# Clock_Control_Reg_CM register map
Vendor: Texas Instruments
Peripheral module from a debugger description file (folder omap34xx).
Registers are 32-bit, access per field, reset 0x0 unless marked. A register's access mark holds for its fields unless they carry their own. Offsets are as the file gives them; lines under a group give offsets from that group; [hi:lo] are bit positions; {n}, {i} and the like mark numbered series; 'fields as' and 'values as' point back to an identical list; <NAME> marks a mode.

## Clock_Control_Reg_CM
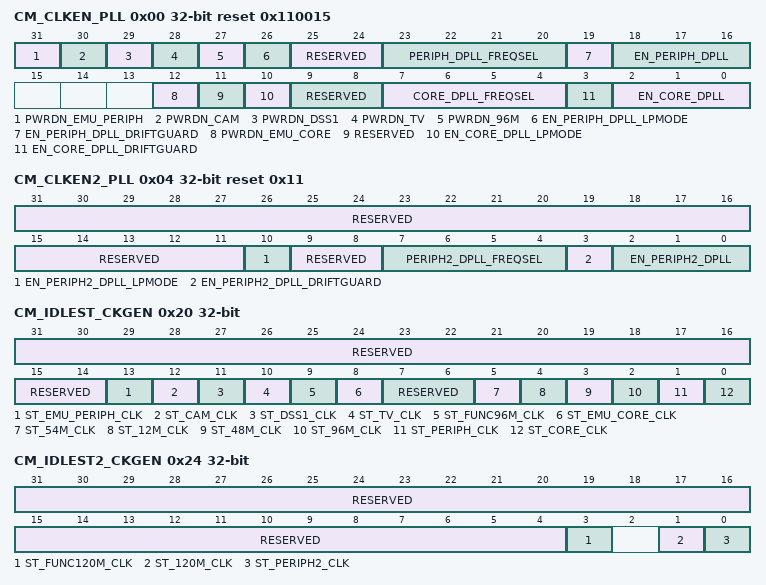
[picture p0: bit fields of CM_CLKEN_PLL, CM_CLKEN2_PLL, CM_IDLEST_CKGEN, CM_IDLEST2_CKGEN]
0x00 CM_CLKEN_PLL reset 0x110015 — This register allows controlling the DPLL3 and DPLL4 modes.
  [31] PWRDN_EMU_PERIPH rw — This bit allows to power-down or not the DPLL4_M6X2_CLK HSDIVIDER path.
    0=Power-up the DPLL4_M6X2_CLK HSDIVIDER path; 1=Power-down the DPLL4_M6X2_CLK HSDIVIDER path. Writting this bit to 1 will take effect immediatly.
  [30] PWRDN_CAM rw — This bit allows to power-down or not the DPLL4_M5X2_CLK HSDIVIDER path.
    0=Power-up the DPLL4_M5X2_CLK HSDIVIDER path; 1=Power-down the DPLL4_M5X2_CLK HSDIVIDER path. Writting this bit to 1 will take effect immediatly.
  [29] PWRDN_DSS1 rw — This bit allows to power-down or not the DPLL4_M4X2_CLK HSDIVIDER path.
    0=Power-up the DPLL4_M4X2_CLK HSDIVIDER path; 1=Power-down the DPLL4_M4X2_CLK HSDIVIDER path. Writting this bit to 1 will take effect immediatly.
  [28] PWRDN_TV rw — This bit allows to power-down or not the DPLL4_M3X2_CLK HSDIVIDER path.
    0=Power-up the DPLL4_M3X2_CLK HSDIVIDER path; 1=Power-down the DPLL4_M3X2_CLK HSDIVIDER path. Writting this bit to 1 will take effect immediatly.
  [27] PWRDN_96M rw — This bit allows to power-down or not the DPLL4_M2X2_CLK path.
    0=Power-up the DPLL4_M2X2_CLK path; 1=Power-down the DPLL4_M2X2_CLK path. Writting this bit to 1 will take effect immediatly.
  [26] EN_PERIPH_DPLL_LPMODE rw — This bit allows to enable or disable the LP mode of the DPLL4. Writting this bit to switch the mode between LP or normal mode will take effect only when the DPLL will have transition into the bypass or stop state, followed by a lock or re-lock of the DPLL.
    0=Disables the DPLL LP mode to re-enter the normal mode at the following lock or re-lock sequence; 1=Enables the DPLL LP mode to enter the LP mode at the following lock or re-lock sequence
  [25:24] RESERVED rw — Write 0s for future compatibility. Read returns 0.
  [23:20] PERIPH_DPLL_FREQSEL rw — This bit field allows selecting the proper range of the DPLL4 internal frequency depending on the DPLL reference clock and the N divider.
    3=0.75 MHz 1.0 MHz0x4: 1.0 MHz 1.25 MHz 0x5: 1.25 MHz 1.5 MHz 0x6: 1.5 MHz 1.75 MHz 0x7: 1.75 MHz 2.1 MHz 0xB: 7.5 MHz 10 MHz 0xC: 10 MHz 12.5 MHz 0xD: 12.5 MHz 15 MHz 0xE: 15 MHz 17.5 MHz 0xF: 17.5 MHz 21 MHz
  [19] EN_PERIPH_DPLL_DRIFTGUARD rw — This bit allows to enable or disable the automatic recalibration feature of the DPLL4. The DPLL4 will automatically start a recalibration process upon assertion of the recal flag if this bit is set.
    0=Disables the DPLL4 automatic recalibration mode; 1=Enables the DPLL4 automatic recalibration mode
  [18:16] EN_PERIPH_DPLL rw — DPLL4 control; Other enums: Reserved
    1=Put the DPLL4 in low power stop mode; 7=Enables the DPLL4 in lock mode
  [12] PWRDN_EMU_CORE rw — This bit allows to power-down or not the DPLL3_M3X2 HSDIVIDER path.
    0=Power-up the DPLL3_M3X2 HSDIVIDER path; 1=Power-down the DPLL3_M3X2 HSDIVIDER path. Writting this bit to 1 will take effect immediatly.
  [11] RESERVED ro — Write 0s for future compatibility. Read returns 0.
  [10] EN_CORE_DPLL_LPMODE rw — This bit allows to enable or disable the LP mode of the DPLL3. Writting this bit to switch the mode between LP or normal mode will take effect only when the DPLL will have transition into the bypass or stop state, followed by a lock or re-lock of the DPLL.
    values as EN_PERIPH_DPLL_LPMODE
  [9:8] RESERVED rw — Write 0s for future compatibility. Read returns 0.
  [7:4] CORE_DPLL_FREQSEL rw — This bit field allows selecting the proper range of the DPLL3 internal frequency depending on the DPLL reference clock and the N divider.
    values as PERIPH_DPLL_FREQSEL
  [3] EN_CORE_DPLL_DRIFTGUARD rw — This bit allows to enable or disable the automatic recalibration feature of the DPLL3. The DPLL3 will automatically start a recalibration process upon assertion of the recal flag if this bit is set.
    0=Disables the DPLL3 automatic recalibration mode; 1=Enables the DPLL3 automatic recalibration mode
  [2:0] EN_CORE_DPLL rw — DPLL3 control; Other enums: Reserved
    5=Put the DPLL3 in low power bypass; 6=Put the DPLL3 in fast relock bypass; 7=Enables the DPLL3 in lock mode
0x04 CM_CLKEN2_PLL reset 0x11 — This register controls the DPLL5 modes.
  [31:11] RESERVED ro — Write 0s for future compatibility. Read returns 0.
  [10] EN_PERIPH2_DPLL_LPMODE rw — This bit allows to enable or disable the LP mode of the DPLL5. Writting this bit to switch the mode between LP or normal mode will take effect only when the DPLL will have transition into the bypass or stop state, followed by a lock or re-lock of the DPLL.
    values as CM_CLKEN_PLL.EN_PERIPH_DPLL_LPMODE
  [9:8] RESERVED rw — Write 0s for future compatibility. Read returns 0.
  [7:4] PERIPH2_DPLL_FREQSEL rw — This bit field allows selecting the proper range of the second PERIPHERAL DPLL internal frequency depending on the DPLL reference clock and the N divider.
    values as CM_CLKEN_PLL.PERIPH_DPLL_FREQSEL
  [3] EN_PERIPH2_DPLL_DRIFTGUARD rw — This bit allows to enable or disable the automatic recalibration feature of the DPLL5. The DPLL5 will automatically start a recalibration process upon assertion of the recal flag if this bit is set.
    0=Disables the DPLL5 automatic recalibration mode; 1=Enables the DPLL5 automatic recalibration mode
  [2:0] EN_PERIPH2_DPLL rw — DPLL5 control; Other enums: Reserved
    1=Put the second DPLL5 in low power stop mode; 7=Enables the DPLL5 in lock mode
0x20 CM_IDLEST_CKGEN ro — This register allows monitoring the master clock activity. This register is read only and automatically updated.
  [31:14] RESERVED — Read returns 0.
  [13] ST_EMU_PERIPH_CLK — Emulation clock activity at the output stage of the DPLL4
    0=EMU_PER_ALWON_CLK is not active; 1=EMU_PER_ALWON_CLK is active
  [12] ST_CAM_CLK — CAMERA functional clock activity at the output stage of the DPLL4
    0=CAM_MCLK is not active; 1=CAM_MCLK is active
  [11] ST_DSS1_CLK — DSS functional clock 1 activity at the output stage of the DPLL4
    0=DSS1_ALWON_FCLK is not active; 1=DSS1_ALWON_FCLK is active
  [10] ST_TV_CLK — TV clock activity at the output stage of the DPLL4
    0=DPLL4_M3X2_CLK is not active; 1=DPLL4_M3X2_CLK is active
  [9] ST_FUNC96M_CLK — 96 MHz clock activity at the output stage of the DPLL4
    0=DPLL4_M2X2_CLK is not active; 1=DPLL4_M2X2_CLK is active
  [8] ST_EMU_CORE_CLK — Emulation clock activity at the output stage of the DPLL3
    0=EMU_CORE_ALWON_CLK is not active; 1=EMU_CORE_ALWON_CLK is active
  [7:6] RESERVED — Read returns 0.
  [5] ST_54M_CLK — Functional clock 54 MHz activity
    0=54MHz clock is not active; 1=54MHz clock is active
  [4] ST_12M_CLK — Functional clock 12 MHz activity
    0=12M_FCLK is not active; 1=12M_FCLK is active
  [3] ST_48M_CLK — Functional clock 48 MHz activity
    0=48M_FCLK is not active; 1=48M_FCLK is active
  [2] ST_96M_CLK — Functional clock 96 MHz activity
    0=96M_FCLK is not active; 1=96M_FCLK is active
  [1] ST_PERIPH_CLK — DPLL4 clock activity
    0=DPLL4 is bypassed; 1=DPLL4 is locked
  [0] ST_CORE_CLK — DPLL3 clock activity
    0=DPLL3 is bypassed; 1=DPLL3 is locked
0x24 CM_IDLEST2_CKGEN ro — This register allows monitoring the master clock activity. This register is read only and automatically updated.
  [31:4] RESERVED — Read returns 0.
  [3] ST_FUNC120M_CLK — 120-MHz clock activity at the output stage of the DPLL5
    0=DPLL5_M2_CLK is not active; 1=DPLL5_M2_CLK is active
  [1] ST_120M_CLK — USB HOST functional clock 120-MHz activity
    0=USB HOST 120M_FCLK is not active; 1=USB HOST 120M_FCLK is active
  [0] ST_PERIPH2_CLK — DPLL5 clock activity
    0=DPLL5 is bypassed; 1=DPLL5 is locked
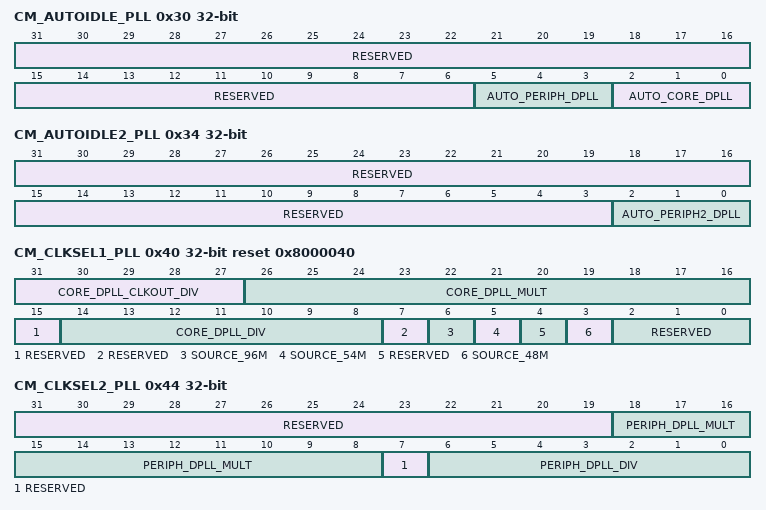
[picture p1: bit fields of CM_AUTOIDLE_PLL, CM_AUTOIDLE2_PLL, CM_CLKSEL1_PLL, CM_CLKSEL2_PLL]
0x30 CM_AUTOIDLE_PLL — This register provides automatic control over the DPLL3 and DPLL4 activity.
  [31:6] RESERVED ro — Write 0s for future compatibility. Read returns 0.
  [5:3] AUTO_PERIPH_DPLL rw — DPLL4 automatic control; Other enums: Reserved
    0=Auto control disabled; 1=DPLL4 is automatically put in low power stop mode when none of the 96 MHz and 54 MHz clocks are required anymore. It is also restarted automatically.
  [2:0] AUTO_CORE_DPLL rw — DPLL3 automatic control; Other enums: Reserved
    0=Auto control disabled; 1=DPLL3 is automatically put in low power stop mode when the CORE clock is not required anymore. It is also restarted automatically.; 5=DPLL3 is automatically put in idle bypass low power mode when the CORE clock is not required anymore. It is also restarted automatically.
0x34 CM_AUTOIDLE2_PLL — This register provides automatic control over the DPLL5 activity.
  [31:3] RESERVED ro — Write 0s for future compatibility. Read returns 0.
  [2:0] AUTO_PERIPH2_DPLL rw — DPLL5 automatic control; Other enums: Reserved
    0=Auto control disabled; 1=DPLL5 is automatically put in low power stop mode when the 120 MHz clock is not required anymore. It is also restarted automatically.
0x40 CM_CLKSEL1_PLL reset 0x8000040 — This register controls the selection of the master clock frequencies.
  [31:27] CORE_DPLL_CLKOUT_DIV rw — DPLL3 output clock divider factor M2; Other enums: Reserved
    {v}=DPLL3 output clock is divided by {v} (v=1..31)
  [26:16] CORE_DPLL_MULT rw — DPLL3 multiplier factor (0 to 2047)
  [15] RESERVED ro — Write 0s for future compatibility. Read returns 0.
  [14:8] CORE_DPLL_DIV rw — DPLL3 divider factor (0 to 127)
  [7] RESERVED ro — Write 0s for future compatibility. Read returns 0.
  [6] SOURCE_96M rw — Selection of 96M_FCLK source
    0=source is the CM_96M_FCLK; 1=source is CM_SYS_CLK
  [5] SOURCE_54M rw — Selection of 54MHz clock source
    0=source is the DPLL4_M3X2_CLK; 1=source is sys_altclk
  [4] RESERVED ro — Write 0s for future compatibility. Read returns 0.
  [3] SOURCE_48M rw — Selection of Func_12M_clk and Func_48M_clk source
    0=source is the CM_96M_FCLK; 1=source is sys_altclk
  [2:0] RESERVED ro — Write 0s for future compatibility. Read returns 0.
0x44 CM_CLKSEL2_PLL — This register controls the selection of the master clock frequencies.
  [31:19] RESERVED ro — Write 0s for future compatibility. Read returns 0.
  [18:8] PERIPH_DPLL_MULT rw — DPLL4 multiplier factor (0 to 2047)
  [7] RESERVED ro — Write 0s for future compatibility. Read returns 0.
  [6:0] PERIPH_DPLL_DIV rw — DPLL4 divider factor (0 to 127)
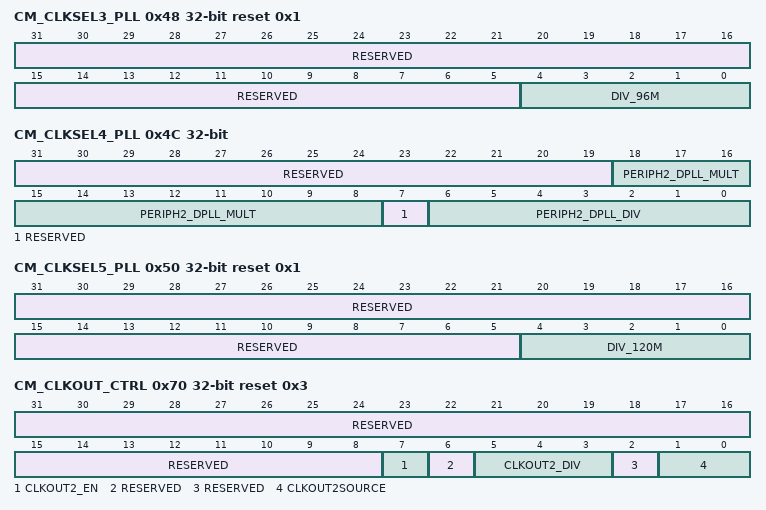
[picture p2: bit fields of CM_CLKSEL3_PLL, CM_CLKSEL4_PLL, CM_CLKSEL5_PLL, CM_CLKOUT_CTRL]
0x48 CM_CLKSEL3_PLL reset 0x1 — This register controls the selection of the master clock frequencies.
  [31:5] RESERVED ro — Write 0s for future compatibility. Read returns 0.
  [4:0] DIV_96M rw — 96 MHz clock divider factor M2 (1 up to 16); Other enums: Reserved
    {v}=96 MHz clock is DPLL4 clock divided by {v} (v=1..16)
0x4C CM_CLKSEL4_PLL — This register controls the selection of the master clock frequencies.
  [31:19] RESERVED ro — Write 0s for future compatibility. Read returns 0.
  [18:8] PERIPH2_DPLL_MULT rw — DPLL5 multiplier factor (0 to 2047)
  [7] RESERVED ro — Write 0s for future compatibility. Read returns 0.
  [6:0] PERIPH2_DPLL_DIV rw — DPLL5 divider factor (0 to 127)
0x50 CM_CLKSEL5_PLL reset 0x1 — This register controls the selection of the master clock frequencies.
  [31:5] RESERVED ro — Write 0s for future compatibility. Read returns 0.
  [4:0] DIV_120M rw — 120 MHz clock divider factor M2 (1 up to 16); Other enums: Reserved
    {v}=120 MHz clock is DPLL5 clock divided by {v} (v=1..16)
0x70 CM_CLKOUT_CTRL reset 0x3 — This register provides control over the SYS_CLKOUT2 output clock.
  [31:8] RESERVED ro — Write 0s for future compatibility. Read returns 0.
  [7] CLKOUT2_EN rw — This bit controls the external output clock activity
    0=sys_clkout2 is disabled; 1=sys_clkout2 is enabled
  [6] RESERVED ro — Write 0s for future compatibility. Read returns 0.
  [5:3] CLKOUT2_DIV rw — This field controls the external output clock division; Other enums: Reserved
    0=sys_clkout2 / 1; 1=sys_clkout2 / 2; 2=sys_clkout2 / 4; 3=sys_clkout2 / 8; 4=sys_clkout2 / 16
  [2] RESERVED ro — Write 0s for future compatibility. Read returns 0.
  [1:0] CLKOUT2SOURCE rw — This field selects the external output clock source
    0=source is CORE_CLK; 1=source is CM_SYS_CLK; 2=source is CM_96M_FCLK; 3=source is 54 MHz clock
